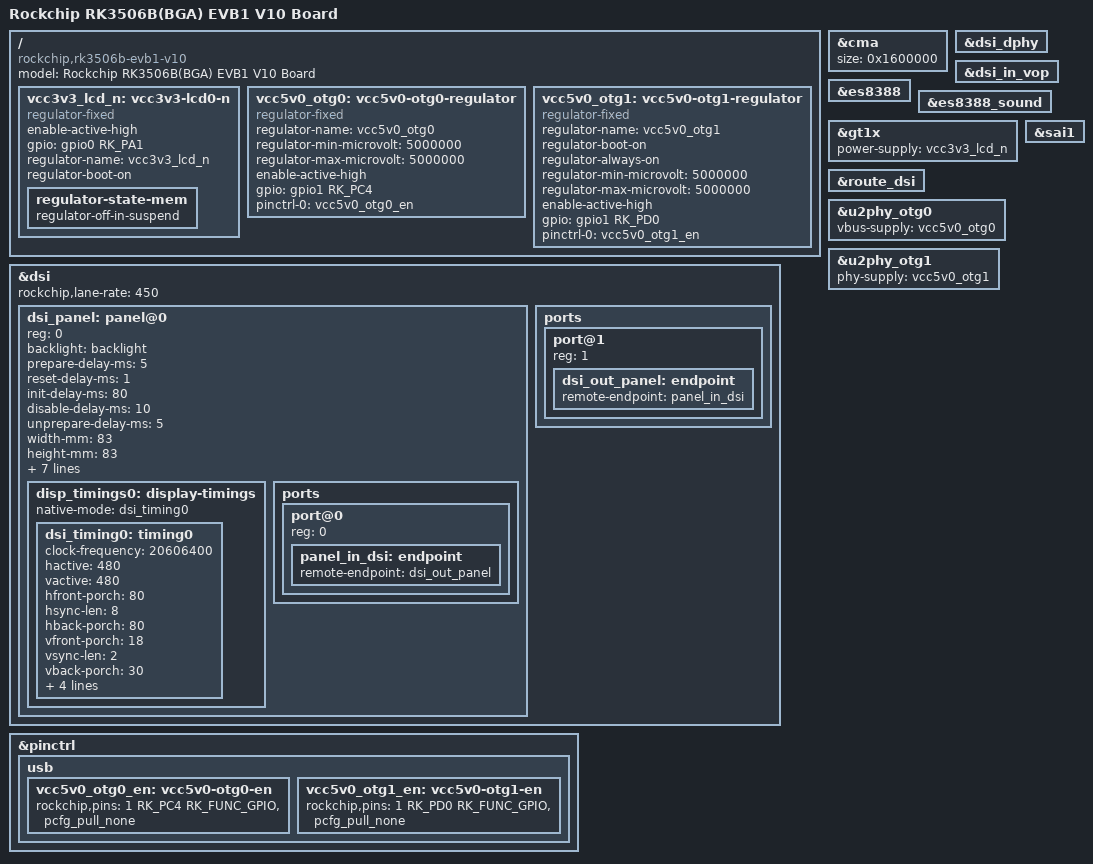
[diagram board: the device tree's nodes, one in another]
// SPDX-License-Identifier: (GPL-2.0+ OR MIT)
/*
 * Copyright (c) 2024 Rockchip Electronics Co., Ltd.
 */

/dts-v1/;

#include "rk3506.dtsi"
#include "rk3506-evb1-v10.dtsi"

/ {
	model = "Rockchip RK3506B(BGA) EVB1 V10 Board";
	compatible = "rockchip,rk3506b-evb1-v10", "rockchip,rk3506";

	vcc3v3_lcd_n: vcc3v3-lcd0-n {
		compatible = "regulator-fixed";
		enable-active-high;
		gpio = <&gpio0 RK_PA1 GPIO_ACTIVE_HIGH>;
		regulator-name = "vcc3v3_lcd_n";
		regulator-boot-on;
		regulator-state-mem {
			regulator-off-in-suspend;
		};
	};

	vcc5v0_otg0: vcc5v0-otg0-regulator {
		compatible = "regulator-fixed";
		regulator-name = "vcc5v0_otg0";
		regulator-min-microvolt = <5000000>;
		regulator-max-microvolt = <5000000>;
		enable-active-high;
		gpio = <&gpio1 RK_PC4 GPIO_ACTIVE_HIGH>;
		pinctrl-names = "default";
		pinctrl-0 = <&vcc5v0_otg0_en>;
	};

	vcc5v0_otg1: vcc5v0-otg1-regulator {
		compatible = "regulator-fixed";
		regulator-name = "vcc5v0_otg1";
		regulator-boot-on;
		regulator-always-on;
		regulator-min-microvolt = <5000000>;
		regulator-max-microvolt = <5000000>;
		enable-active-high;
		gpio = <&gpio1 RK_PD0 GPIO_ACTIVE_HIGH>;
		pinctrl-names = "default";
		pinctrl-0 = <&vcc5v0_otg1_en>;
	};
};

&cma {
	size = <0x1600000>;
};

&dsi {
	status = "okay";
	
	rockchip,lane-rate = <450>;
	dsi_panel: panel@0 {
		status = "okay"
		compatible = "simple-panel-dsi";
		reg = <0>;
		backlight = <&backlight>;
		prepare-delay-ms = <5>;
		reset-delay-ms = <1>;
		init-delay-ms = <80>;
		disable-delay-ms = <10>;
		unprepare-delay-ms = <5>;

		width-mm = <83>;
		height-mm = <83>;

		dsi,flags = <(MIPI_DSI_MODE_VIDEO | MIPI_DSI_MODE_VIDEO_BURST |
			      MIPI_DSI_MODE_LPM | MIPI_DSI_MODE_NO_EOT_PACKET)>;
		dsi,format = <MIPI_DSI_FMT_RGB888>;
		dsi,lanes  = <2>;
		panel-init-sequence = [
			39 00 06 ff 77 01 00 00 10
			39 00 03 c0 3b 00
			39 00 03 c1 0d 02
			39 00 03 c2 21 08
			39 00 11 b0 00 11 18 0e 11 06 07 08 07 22 04 12 0f aa 31 18
			39 00 11 b1 00 11 19 0e 12 07 08 08 08 22 04 11 11 a9 32 18
			39 00 06 ff 77 01 00 00 11
			15 00 02 b0 60
			15 00 02 b1 30
			15 00 02 b2 87
			15 00 02 b3 80
			15 00 02 b5 49
			15 00 02 b7 85
			15 00 02 b8 21
			15 00 02 c1 78
			15 14 02 c2 78
			39 00 04 e0 00 1b 02
			39 00 0c e1 08 a0 00 00 07 a0 00 00 00 44 44
			39 00 0d e2 11 11 44 44 ed a0 00 00 ec a0 00 00
			39 00 05 e3 00 00 11 11
			39 00 03 e4 44 44
			39 00 11 e5 0a e9 d8 a0 0c eb d8 a0 0e ed d8 a0 10 ef d8 a0
			39 00 05 e6 00 00 11 11
			39 00 03 e7 44 44
			39 00 11 e8 09 e8 d8 a0 0b ea d8 a0 0d ec d8 a0 0f ee d8 a0
			39 00 08 eb 02 00 e4 e4 88 00 40
			39 00 03 ec 3c 00
			39 00 11 ed ab 89 76 54 02 ff ff ff ff ff ff 20 45 67 98 ba
			/*
			39 00 06 ff 77 01 00 00 12
			15 00 02 d1 81
			15 00 02 d2 08
			*/
			39 00 06 ff 77 01 00 00 00
			15 00 02 36 00
			05 c8 01 11
			05 32 01 29
		];

		disp_timings0: display-timings {
			native-mode = <&dsi_timing0>;
			dsi_timing0: timing0 {
				clock-frequency = <20606400>;
				hactive = <480>;
				vactive = <480>;
				hfront-porch = <80>;
				hsync-len = <8>;
				hback-porch = <80>;
				vfront-porch = <18>;
				vsync-len = <2>;
				vback-porch = <30>;
				hsync-active = <0>;
				vsync-active = <0>;
				de-active = <0>;
				pixelclk-active = <0>;
			};
		};

		ports {
			#address-cells = <1>;
			#size-cells = <0>;

			port@0 {
				reg = <0>;
				panel_in_dsi: endpoint {
					remote-endpoint = <&dsi_out_panel>;
				};
			};
		};
	};

	ports {
		#address-cells = <1>;
		#size-cells = <0>;

		port@1 {
			reg = <1>;
			dsi_out_panel: endpoint {
				remote-endpoint = <&panel_in_dsi>;
			};
		};
	};
};

&dsi_dphy {
	status = "okay";
};

&dsi_in_vop {
	status = "okay";
};

&dsi_panel {
	power-supply = <&vcc3v3_lcd_n>;
};

&es8388 {
	status = "okay";
};

&es8388_sound {
	status = "okay";
};

&gt1x {
	power-supply = <&vcc3v3_lcd_n>;
	status = "okay";
};

&pinctrl {
	usb {
		vcc5v0_otg0_en: vcc5v0-otg0-en {
			rockchip,pins = <1 RK_PC4 RK_FUNC_GPIO &pcfg_pull_none>;
		};

		vcc5v0_otg1_en: vcc5v0-otg1-en {
			rockchip,pins = <1 RK_PD0 RK_FUNC_GPIO &pcfg_pull_none>;
		};
	};
};

&route_dsi {
	status = "okay";
};

&sai1 {
	status = "okay";
};

&u2phy_otg0 {
	vbus-supply = <&vcc5v0_otg0>;
	status = "okay";
};

&u2phy_otg1 {
	phy-supply = <&vcc5v0_otg1>;
	status = "okay";
};
